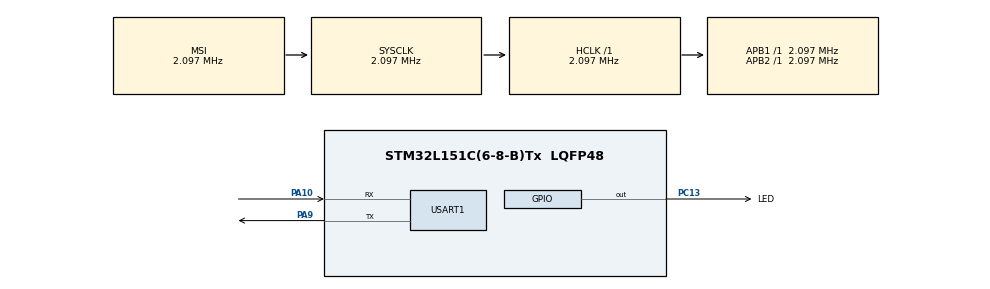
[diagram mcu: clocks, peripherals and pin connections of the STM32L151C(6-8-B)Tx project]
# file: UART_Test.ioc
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Mcu.Family=STM32L1
Mcu.Name=STM32L151C(6-8-B)Tx
Mcu.Package=LQFP48
NVIC.PriorityGroup=NVIC_PRIORITYGROUP_4
PA10.Mode=Asynchronous
PA10.Signal=USART1_RX
PA13.Mode=Serial_Wire
PA13.Signal=SYS_JTMS-SWDIO
PA14.Mode=Serial_Wire
PA14.Signal=SYS_JTCK-SWCLK
PA9.Mode=Asynchronous
PA9.Signal=USART1_TX
PC13-WKUP2.GPIO_Label=LED
PC13-WKUP2.GPIO_ModeDefaultOutputPP=GPIO_MODE_OUTPUT_OD
PC13-WKUP2.GPIO_PuPd=GPIO_NOPULL
PC13-WKUP2.GPIO_Speed=GPIO_SPEED_FREQ_LOW
PC13-WKUP2.PinState=GPIO_PIN_SET
PC13-WKUP2.Signal=GPIO_Output
ProjectManager.HeapSize=0x200
ProjectManager.StackSize=0x400
ProjectManager.TargetToolchain=MDK-ARM V5.32
RCC.AHBFreq_Value=2097000
RCC.APB1Freq_Value=2097000
RCC.APB2Freq_Value=2097000
RCC.HSE_VALUE=24000000
RCC.HSI_VALUE=16000000
RCC.LSE_VALUE=32768
RCC.MSI_VALUE=2097000
RCC.SYSCLKFreq_VALUE=2097000
RCC.VCOOutputFreq_Value=48000000
USART1.VirtualMode=VM_ASYNC
board=custom

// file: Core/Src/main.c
/* USER CODE BEGIN Header */
/**
  ******************************************************************************
  * @file           : main.c
  * @brief          : Main program body
  ******************************************************************************
  * @attention
  *
  * Copyright (c) 2026 STMicroelectronics.
  * All rights reserved.
  *
  * This software is licensed under terms that can be found in the LICENSE file
  * in the root directory of this software component.
  * If no LICENSE file comes with this software, it is provided AS-IS.
  *
  ******************************************************************************
  */
/* USER CODE END Header */
#include "main.h"
#include "usart.h"
#include "gpio.h"

/* USER CODE BEGIN Includes */
#include <string.h>
/* USER CODE END Includes */

/* USER CODE BEGIN PV */
uint8_t u8Number=0x5A;
	uint8_t u8byte[]={0x23,0xFE,0x00,0x01,0x39,0x02,0x01,0x01,0x06,0x01,0x01,0x02,0x10,0x00,0x05,0x01,0x23,0x23};
  char ch='A';
	char *strbuf="Fuck Me";
/* USER CODE END PV */

void SystemClock_Config(void);

int main(void)
{

  /* MCU Configuration--------------------------------------------------------*/

  /* Reset of all peripherals, Initializes the Flash interface and the Systick. */
  HAL_Init();

  /* Configure the system clock */
  SystemClock_Config();

  /* Initialize all configured peripherals */
  MX_GPIO_Init();
  MX_USART1_UART_Init();
  /* USER CODE BEGIN 2 */
	HAL_UART_Transmit(&huart1,&u8Number,1,HAL_MAX_DELAY);
	HAL_UART_Transmit(&huart1,u8byte,18,HAL_MAX_DELAY);
	HAL_UART_Transmit(&huart1,(uint8_t*)&ch,1,HAL_MAX_DELAY);
	HAL_UART_Transmit(&huart1,(uint8_t*)&strbuf,strlen(strbuf),HAL_MAX_DELAY);
  /* USER CODE END 2 */

  /* Infinite loop */
  while (1)
  {

  }
}

void SystemClock_Config(void)
{
  RCC_OscInitTypeDef RCC_OscInitStruct = {0};
  RCC_ClkInitTypeDef RCC_ClkInitStruct = {0};

  /** Configure the main internal regulator output voltage
  */
  __HAL_PWR_VOLTAGESCALING_CONFIG(PWR_REGULATOR_VOLTAGE_SCALE1);

  /** Initializes the RCC Oscillators according to the specified parameters
  * in the RCC_OscInitTypeDef structure.
  */
  RCC_OscInitStruct.OscillatorType = RCC_OSCILLATORTYPE_MSI;
  RCC_OscInitStruct.MSIState = RCC_MSI_ON;
  RCC_OscInitStruct.MSICalibrationValue = 0;
  RCC_OscInitStruct.MSIClockRange = RCC_MSIRANGE_5;
  RCC_OscInitStruct.PLL.PLLState = RCC_PLL_NONE;
  if (HAL_RCC_OscConfig(&RCC_OscInitStruct) != HAL_OK)
  {
    Error_Handler();
  }

  /** Initializes the CPU, AHB and APB buses clocks
  */
  RCC_ClkInitStruct.ClockType = RCC_CLOCKTYPE_HCLK|RCC_CLOCKTYPE_SYSCLK
                              |RCC_CLOCKTYPE_PCLK1|RCC_CLOCKTYPE_PCLK2;
  RCC_ClkInitStruct.SYSCLKSource = RCC_SYSCLKSOURCE_MSI;
  RCC_ClkInitStruct.AHBCLKDivider = RCC_SYSCLK_DIV1;
  RCC_ClkInitStruct.APB1CLKDivider = RCC_HCLK_DIV1;
  RCC_ClkInitStruct.APB2CLKDivider = RCC_HCLK_DIV1;

  if (HAL_RCC_ClockConfig(&RCC_ClkInitStruct, FLASH_LATENCY_0) != HAL_OK)
  {
    Error_Handler();
  }
}

void Error_Handler(void)
{
  __disable_irq();
  while (1)
  {
  }
}
